AUTOSAR XML (schema 4-2-2)
package /Components
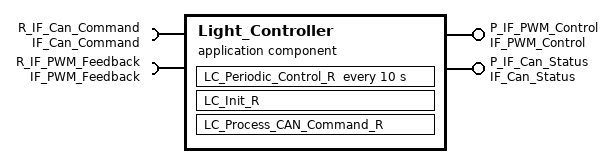
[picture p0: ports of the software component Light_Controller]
  application sw component type Light_Controller
    provide port P_IF_PWM_Control: provided-interface=IF_PWM_Control
    provide port P_IF_Can_Status: provided-interface=IF_Can_Status
    provide/require port PR_IF_Light_Params: provided-required-interface=IF_Light_Params
    require port R_IF_Can_Command: required-interface=IF_Can_Command
    require port R_IF_PWM_Feedback: required-interface=IF_PWM_Feedback
    behavior Light_Controller_InternalBehavior
      data received event LC_CAN_Command_Received: start-on-event=LC_Process_CAN_Command_R
      init event LC_Init_Event: start-on-event=LC_Init_R
      timing event LC_Periodic_10ms: start-on-event=LC_Periodic_Control_R, period=10
      runnable LC_Init_R
        4 x parameter access:
          ParamAccess_PwmMaxDuty: accessed-parameter=PR_IF_Light_Params.pwm_max_duty
          ParamAccess_PwmMinDuty: accessed-parameter=PR_IF_Light_Params.pwm_min_duty
          ParamAccess_FaultCurrentThreshold: accessed-parameter=PR_IF_Light_Params.fault_current_threshold
          ParamAccess_RetryCount: accessed-parameter=PR_IF_Light_Params.retry_count
      runnable LC_Process_CAN_Command_R
        data-receive-point-by-arguments:
          7 x access:
            Recv_Headlamp_On_Cmd: accessed-variable=R_IF_Can_Command.headlamp_on_cmd
            Recv_TailLamp_On_Cmd: accessed-variable=R_IF_Can_Command.tail_lamp_on_cmd
            Recv_LeftTurn_Cmd: accessed-variable=R_IF_Can_Command.left_turn_cmd
            Recv_RightTurn_Cmd: accessed-variable=R_IF_Can_Command.right_turn_cmd
            Recv_Headlamp_Brightness_Cmd: accessed-variable=R_IF_Can_Command.headlamp_brightness_cmd
            Recv_Tail_Brightness_Cmd: accessed-variable=R_IF_Can_Command.tail_brightness_cmd
            Recv_Turn_Brightness_Cmd: accessed-variable=R_IF_Can_Command.turn_brightness_cmd
        data-send-points:
          4 x access:
            Send_Headlamp_Duty_SP: accessed-variable=P_IF_PWM_Control.headlamp_duty_setpoint
            Send_TailLamp_Duty_SP: accessed-variable=P_IF_PWM_Control.tail_lamp_duty_setpoint
            Send_LeftTurn_Duty_SP: accessed-variable=P_IF_PWM_Control.left_turn_duty_setpoint
            Send_RightTurn_Duty_SP: accessed-variable=P_IF_PWM_Control.right_turn_duty_setpoint
      runnable LC_Periodic_Control_R: minimum-start-interval=10
        data-read-access:
          5 x access:
            Read_Headlamp_Current_Brightness: accessed-variable=R_IF_PWM_Feedback.headlamp_current_brightness
            Read_TailLamp_Current_Brightness: accessed-variable=R_IF_PWM_Feedback.tail_lamp_current_brightness
            Read_LeftTurn_Status_FB: accessed-variable=R_IF_PWM_Feedback.left_turn_status
            Read_RightTurn_Status_FB: accessed-variable=R_IF_PWM_Feedback.right_turn_status
            Read_Lamp_Fault_Code_FB: accessed-variable=R_IF_PWM_Feedback.lamp_fault_code
        data-send-points:
          5 x access:
            Send_Headlamp_Status: accessed-variable=P_IF_Can_Status.headlamp_status
            Send_TailLamp_Status: accessed-variable=P_IF_Can_Status.tail_lamp_status
            Send_LeftTurn_Status: accessed-variable=P_IF_Can_Status.left_turn_status
            Send_RightTurn_Status: accessed-variable=P_IF_Can_Status.right_turn_status
            Send_Fault_Code: accessed-variable=P_IF_Can_Status.fault_code
